# AT32F425 register map
Vendor: Keil; Series: AT32F425; File version: 1.0
CPU: CM4 r0p1, little endian, no MPU, FPU, 4 interrupt priority bits
Registers are 32-bit, read-write, reset 0x0 unless marked. A register's access mark holds for its fields unless they carry their own. Offsets are from the block's base; [hi:lo] are bit positions; {n}, {i} and the like mark numbered series; 'fields as' and 'values as' point back to an identical list.

## ACC — HICK Auto Clock Calibration
Base 0x40006C00
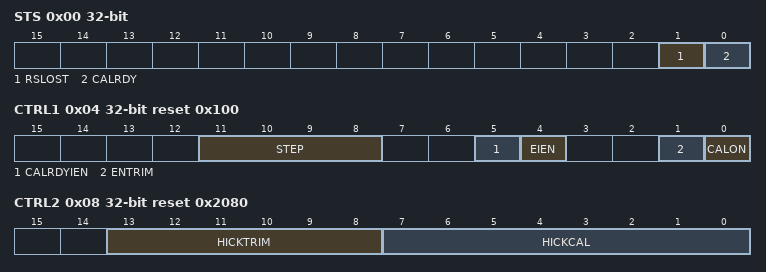
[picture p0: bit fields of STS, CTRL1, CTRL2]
0x00 STS ro — status register
  [1] RSLOST rw — Reference Signal Lost
    0=NotLost (Reference Signal is not lost); 1=Lost (Reference Signal is lost)
  [0] CALRDY rw — Internal high-speed clock calibration ready
    0=NotReady (Interal 8MHz oscillator calibration is not ready); 1=Ready (Interal 8MHz oscillator calibration is ready)
0x04 CTRL1 reset 0x100 — control register 1
  [11:8] STEP — Calibrated step
  [5] CALRDYIEN — CALRDY interrupt enable
    on read: 0=Disabled (Interrupt generation disabled); 1=Enabled (ACC interrupt is generated when CALRDY=1 in the ACC_STS register) | on write: 0=Disable (Interrupt generation disabled); 1=Enable (ACC interrupt is generated when CALRDY=1 in the ACC_STS register)
  [4] EIEN — RSLOST error interrupt enable
    on read: 0=Disabled (Interrupt generation disabled); 1=Enabled (ACC interrupt is generated when RSLOST=1 in the ACC_STS register) | on write: 0=Disable (Interrupt generation disabled); 1=Enable (ACC interrupt is generated when RSLOST=1 in the ACC_STS register)
  [1] ENTRIM — Enable trim
    0=HICKCAL (HICKCAL is calibrated); 1=HICKTRIM (HICKTRIM is calibrated)
  [0] CALON — Calibration on
    on read: 0=Disabled (Calibration disabled); 1=Enabled (Calibration enabled, and starts searching for a pulse on the USB_SOF) | on write: 0=Disable (Calibration disabled); 1=Enable (Calibration enabled, and starts searching for a pulse on the USB_SOF)
0x08 CTRL2 reset 0x2080 — control register 2
  [13:8] HICKTRIM ro — Internal high-speed auto clock trimming
  [7:0] HICKCAL ro — Internal high-speed auto clock calibration
0x0C C1 reset 0x1F2C — compare value 1
  [15:0] C1 — Compare 1
0x10 C2 reset 0x1F40 — compare value 2
  [15:0] C2 — Compare 2
0x14 C3 reset 0x1F54 — compare value 3
  [15:0] C3 — Compare 3

## SCFG — System configuration controller
Base 0x40010000
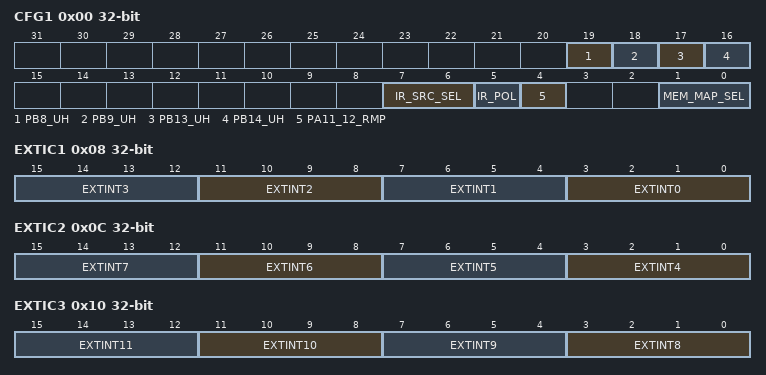
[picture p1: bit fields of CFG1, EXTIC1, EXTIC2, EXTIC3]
0x00 CFG1 — configuration register 1
  [19] PB8_UH — PB8 Ultra high sourcing/sinking strength
  [18] PB9_UH — PB9 Ultra high sourcing/sinking strength
  [17] PB13_UH — PB13 Ultra high sourcing/sinking strength
  [16] PB14_UH — PB14 Ultra high sourcing/sinking strength
  [7:6] IR_SRC_SEL — Infrared modulation envelope signal source selection
  [5] IR_POL — Infrared output polarity selection
  [4] PA11_12_RMP — PA11/PA12 pins remapping bit
  [1:0] MEM_MAP_SEL — Memory mapping selection bits
0x08 EXTIC1 — external interrupt configuration register 1
  [4n+3:4n] EXTINT{n} (n=0..3) — EXTINT {n} configuration bits
0x0C EXTIC2 — external interrupt configuration register 2
  [4n-13:4n-16] EXTINT{n} (n=4..7) — EXTINT {n} configuration bits
0x10 EXTIC3 — external interrupt configuration register 3
  [4n-29:4n-32] EXTINT{n} (n=8..11) — EXTINT {n} configuration bits
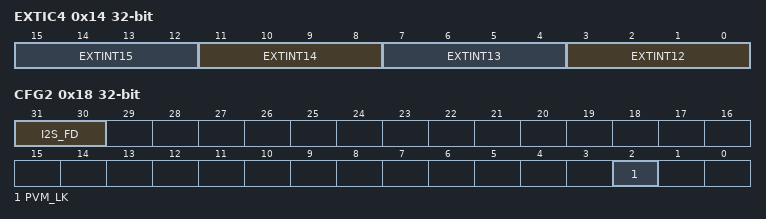
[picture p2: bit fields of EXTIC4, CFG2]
0x14 EXTIC4 — external interrupt configuration register 4
  [4n-45:4n-48] EXTINT{n} (n=12..15) — EXTINT {n} configuration bits
0x18 CFG2 — configuration register 2
  [31:30] I2S_FD — I2S full duplex
  [2] PVM_LK — PVM lock enable

## DEBUG — Debug support
Base 0xE0042000
0x00 IDCODE ro — DEBUG_IDCODE
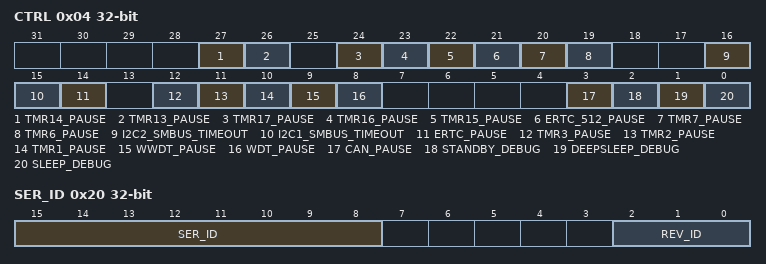
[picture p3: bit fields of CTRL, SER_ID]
0x04 CTRL — DEBUG_CTRL
  [27] TMR14_PAUSE — Timer pause control bit
    0=Continue (The counter clock of TMRx is fed even if the core is halted); 1=Pause (The counter clock of TMRx is stopped when the core is halted)
  [26] TMR13_PAUSE — Timer pause control bit
    values as TMR14_PAUSE
  [24] TMR17_PAUSE — Timer pause control bit
    values as TMR14_PAUSE
  [23] TMR16_PAUSE — Timer pause control bit
    values as TMR14_PAUSE
  [22] TMR15_PAUSE — Timer pause control bit
    values as TMR14_PAUSE
  [21] ERTC_512_PAUSE
  [20] TMR7_PAUSE — Timer pause control bit
    values as TMR14_PAUSE
  [19] TMR6_PAUSE — Timer pause control bit
    values as TMR14_PAUSE
  [16] I2C2_SMBUS_TIMEOUT
  [15] I2C1_SMBUS_TIMEOUT
  [14] ERTC_PAUSE
  [12] TMR3_PAUSE — Timer pause control bit
    values as TMR14_PAUSE
  [11] TMR2_PAUSE — Timer pause control bit
    values as TMR14_PAUSE
  [10] TMR1_PAUSE — Timer pause control bit
    values as TMR14_PAUSE
  [9] WWDT_PAUSE
    values as TMR14_PAUSE
  [8] WDT_PAUSE
    values as TMR14_PAUSE
  [3] CAN_PAUSE
  [2] STANDBY_DEBUG — Debug Standby mode control bit
    on read: 0=Disabled (The whole 1.2V digital circuit is unpowered in Standby mode); 1=Enabled (The whole 1.2V digital circuit is not unpowered in Standby mode, and the system clock is provided by the internal RC oscillator (HICK)) | on write: 0=Disable (The whole 1.2V digital circuit is unpowered in Standby mode); 1=Enable (The whole 1.2V digital circuit is not unpowered in Standby mode, and the system clock is provided by the internal RC oscillator (HICK))
  [1] DEEPSLEEP_DEBUG — Debug Deepsleep mode control bit
    on read: 0=Disabled (In Deepsleep mode, all clocks in the 1.2V domain are disabled); 1=Enabled (In Deepsleep mode, system clock is provided by the internal RC oscillator (HICK)) | on write: 0=Disable (In Deepsleep mode, all clocks in the 1.2V domain are disabled); 1=Enable (In Deepsleep mode, system clock is provided by the internal RC oscillator (HICK))
  [0] SLEEP_DEBUG — Debug Sleep mode control bit
    on read: 0=Disabled (When entering Sleep mode, CPU HCLK clock is disabled, but other clocks remain active); 1=Enabled (When entering Sleep mode, all clocks keep running) | on write: 0=Disable (When entering Sleep mode, CPU HCLK clock is disabled, but other clocks remain active); 1=Enable (When entering Sleep mode, all clocks keep running)
0x20 SER_ID ro — SERIES ID
  [15:8] SER_ID — series ID
  [2:0] REV_ID — version ID
